# USB_USB2SS_GBL_3100C100h register map
Vendor: Texas Instruments
Registers are 32-bit, read-write, reset 0x0 unless marked. A register's access mark holds for its fields unless they carry their own. Offsets are as the file gives them; [hi:lo] are bit positions; {n}, {i} and the like mark numbered series; <NAME> marks a mode.

## USB2SS_GBL (part 3 of 4)
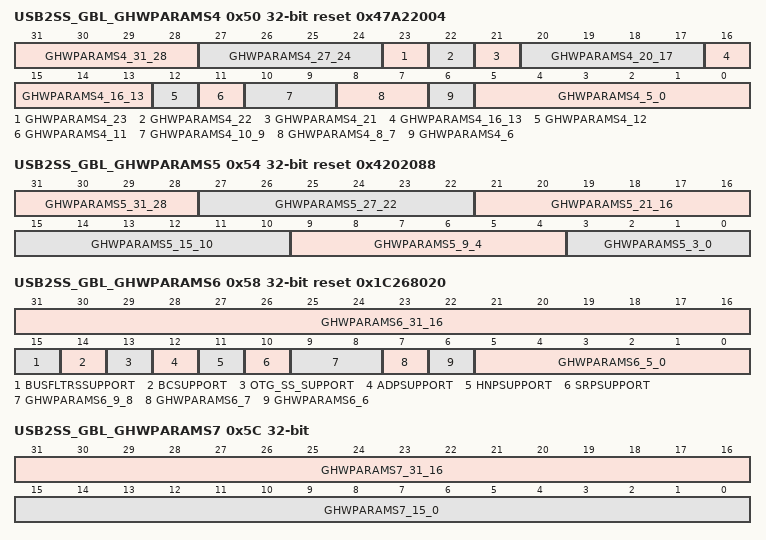
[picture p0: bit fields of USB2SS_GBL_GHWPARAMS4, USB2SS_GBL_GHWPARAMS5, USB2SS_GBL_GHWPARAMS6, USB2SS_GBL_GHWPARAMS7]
0x50 USB2SS_GBL_GHWPARAMS4 ro reset 0x47A22004 — Global Hardware Parameters Register 4This register contains the hardware configuration options that you can select in the coreConsultant GUI. For a description of each parameter, refer to the 'Parameter Descriptions' chapter in the Databook. This information is also available in coreConsultant by right-clicking the parameter label and selecting 'What's This' or by clicking the Help tab. Note: Some of the global hardware parameters are not currently modifiable in coreConsultant. These settings are in the <workspace>/src/DWC_usb3_params.v file. you must not change them.
  [31:28] GHWPARAMS4_31_28 — DWC_USB3_BMU_LSP_DEPTH Reset Source: rst_mod_g_rst_n
  [27:24] GHWPARAMS4_27_24 — DWC_USB3_BMU_PTL_DEPTH-1 Reset Source: rst_mod_g_rst_n
  [23] GHWPARAMS4_23 — DWC_USB3_EN_ISOC_SUPT Reset Source: rst_mod_g_rst_n
  [22] GHWPARAMS4_22 — Reserved Reset Source: rst_mod_g_rst_n
  [21] GHWPARAMS4_21 — DWC_USB3_EXT_BUFF_CONTROL Reset Source: rst_mod_g_rst_n
  [20:17] GHWPARAMS4_20_17 — DWC_USB3_NUM_SS_USB_INSTANCES Reset Source: rst_mod_g_rst_n
  [16:13] GHWPARAMS4_16_13 — DWC_USB3_HIBER_SCRATCHBUFSNumber of external scratchpad buffers the controller requires to save its internal state in the device mode. Each buffer is assumed to be 4KB. The scratchpad buffer array must have this many buffer pointers. Reset Source: rst_mod_g_rst_n
  [12] GHWPARAMS4_12 — Reserved Reset Source: rst_mod_g_rst_n
  [11] GHWPARAMS4_11 — Reserved Reset Source: rst_mod_g_rst_n
  [10:9] GHWPARAMS4_10_9 — Reserved Reset Source: rst_mod_g_rst_n
  [8:7] GHWPARAMS4_8_7 — Reserved Reset Source: rst_mod_g_rst_n
  [6] GHWPARAMS4_6 — Reserved Reset Source: rst_mod_g_rst_n
  [5:0] GHWPARAMS4_5_0 — DWC_USB3_CACHE_TRBS_PER_TRANSFER Reset Source: rst_mod_g_rst_n
0x54 USB2SS_GBL_GHWPARAMS5 ro reset 0x4202088 — Global Hardware Parameters Register 5This register contains the hardware configuration options that you can select in the coreConsultant GUI. For a description of each parameter, refer to the 'Parameter Descriptions' chapter in the Databook. This information is also available in coreConsultant by right-clicking the parameter label and selecting 'What's This' or by clicking the Help tab. Note: Some of the global hardware parameters are not currently modifiable in coreConsultant. These settings are in the <workspace>/src/DWC_usb3_params.v file. you must not change them.
  [31:28] GHWPARAMS5_31_28 — Reserved Reset Source: rst_mod_g_rst_n
  [27:22] GHWPARAMS5_27_22 — DWC_USB3_DFQ_FIFO_DEPTH Reset Source: rst_mod_g_rst_n
  [21:16] GHWPARAMS5_21_16 — DWC_USB3_DWQ_FIFO_DEPTH Reset Source: rst_mod_g_rst_n
  [15:10] GHWPARAMS5_15_10 — DWC_USB3_TXQ_FIFO_DEPTH Reset Source: rst_mod_g_rst_n
  [9:4] GHWPARAMS5_9_4 — DWC_USB3_RXQ_FIFO_DEPTH Reset Source: rst_mod_g_rst_n
  [3:0] GHWPARAMS5_3_0 — DWC_USB3_BMU_BUSGM_DEPTH Reset Source: rst_mod_g_rst_n
0x58 USB2SS_GBL_GHWPARAMS6 ro reset 0x1C268020 — Global Hardware Parameters Register 6This register contains the hardware configuration options that you can select in the coreConsultant GUI. For a description of each parameter, refer to the 'Parameter Descriptions' chapter in the Databook. This information is also available in coreConsultant by right-clicking the parameter label and selecting 'What's This' or by clicking the Help tab. Note: Some of the global hardware parameters are not currently modifiable in coreConsultant. These settings are in the <workspace>/src/DWC_usb3_params.v file. you must not change them.
  [31:16] GHWPARAMS6_31_16 — DWC_USB3_RAM0_DEPTH Reset Source: rst_mod_g_rst_n
  [15] BUSFLTRSSUPPORT — DWC_USB3_EN_BUS_FILTERS Reset Source: rst_mod_g_rst_n
  [14] BCSUPPORT — DWC_USB3_EN_BC Reset Source: rst_mod_g_rst_n
  [13] OTG_SS_SUPPORT — Reserved Reset Source: rst_mod_g_rst_n
  [12] ADPSUPPORT — DWC_USB3_EN_ADP Reset Source: rst_mod_g_rst_n
  [11] HNPSUPPORT — Reserved Reset Source: rst_mod_g_rst_n
  [10] SRPSUPPORT — Reserved Reset Source: rst_mod_g_rst_n
  [9:8] GHWPARAMS6_9_8 — Reserved Reset Source: rst_mod_g_rst_n
  [7] GHWPARAMS6_7 — DWC_USB3_EN_FPGA Reset Source: rst_mod_g_rst_n
  [6] GHWPARAMS6_6 — DWC_USB3_EN_DBG_PORTS Reset Source: rst_mod_g_rst_n
  [5:0] GHWPARAMS6_5_0 — DWC_USB3_PSQ_FIFO_DEPTH Reset Source: rst_mod_g_rst_n
0x5C USB2SS_GBL_GHWPARAMS7 ro — Global Hardware Parameters Register 7This register contains the hardware configuration options that you can select in the coreConsultant GUI. For a description of each parameter, refer to the 'Parameter Descriptions' chapter in the Databook. This information is also available in coreConsultant by right-clicking the parameter label and selecting 'What's This' or by clicking the Help tab. Note: Some of the global hardware parameters are not currently modifiable in coreConsultant. These settings are in the <workspace>/src/DWC_usb3_params.v file. you must not change them.
  [31:16] GHWPARAMS7_31_16 — DWC_USB3_RAM2_DEPTH Reset Source: rst_mod_g_rst_n
  [15:0] GHWPARAMS7_15_0 — DWC_USB3_RAM1_DEPTH Reset Source: rst_mod_g_rst_n
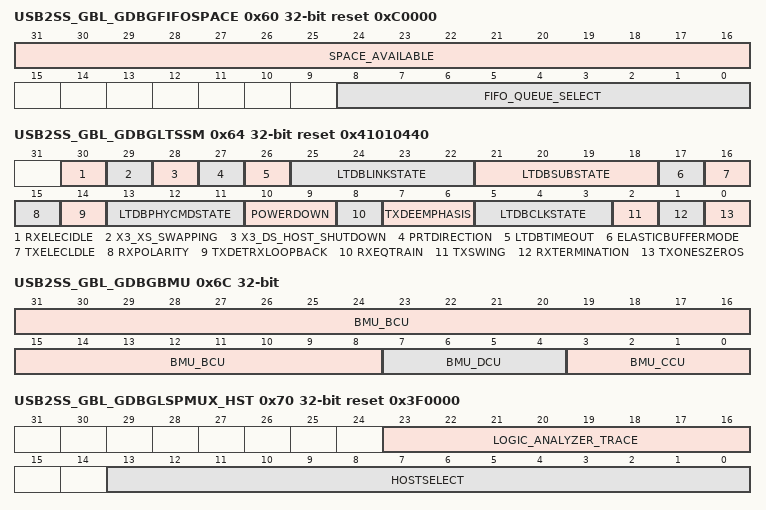
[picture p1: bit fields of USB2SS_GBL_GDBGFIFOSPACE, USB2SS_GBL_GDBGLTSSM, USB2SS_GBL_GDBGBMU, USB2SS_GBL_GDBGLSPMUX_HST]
0x60 USB2SS_GBL_GDBGFIFOSPACE access per field reset 0xC0000 — Global Debug Queue/FIFO Space Available RegisterBit Bash test should not be done on this debug register.
  [31:16] SPACE_AVAILABLE ro — SPACE_AVAILABLE Reset Source: rst_mod_g_rst_n
  [8:0] FIFO_QUEUE_SELECT rw — FIFO/Queue Select [or] Port-Select - FIFO/Queue Select[8:5] indicates the FIFO/Queue Type - FIFO/Queue Select[4:0] indicates the FIFO/Queue NumberFor example, 9'b0_0010_0001 refers to RxFIFO_1 and 9'b0_0101_1110 refers to TxReqQ_30. - 9'b0_0001_1111 to 9'b0_0000_0000: TxFIFO_31 to TxFIFO_0 - 9'b0_0011_1111 to 9'b0_0010_0000: RxFIFO_31 to RxFIFO_0 - 9'b0_0101_1111 to 9'b0_0100_0000: TxReqQ_31 to TxReqQ_0 - 9'b0_0111_1111 to 9'b0_0110_0000: RxReqQ_31 to RxReqQ_0 - 9'b0_1001_1111 to 9'b0_1000_0000: RxInfoQ_31 to RxInfoQ_0 - 9'b0_1010_0000: DescFetchQ_0 [for backwards compatibility] - 9'b0_1010_0001: EventQ_0 [for backwards compatibility] - 9'b0_1010_0010: ProtocolStatusQ_0 - 9'b0_1101_1111 to 9'b0_1110_0000: DescFetchQ_31 to DescFetchQ_0 - 9'b0_1111_1111 to 9'b0_1110_0000: WriteBack/EventQ_31 to WriteBack/EventQ_0 - 9'b1_0000_0111 to 9'b1_0000_0000: AuxEventQ_7 to AuxEventQ_0 [if EN_SEPARATE_DESC_QUEUES=1]Port-Select[3:0] selects the port-number when accessing GDBGLTSSM register. Reset Source: rst_mod_g_rst_n
0x64 USB2SS_GBL_GDBGLTSSM ro reset 0x41010440 — Global Debug LTSSM RegisterIn multi-port host configuration, the port-number is defined by Port-Select[3:0] field in the GDBGFIFOSPACE register. Note: - GDBGLTSSM register is not applicable for USB 2.0-only mode. - Bit Bash test should not be done on this debug register.
  [30] RXELECIDLE — RxElecidleFor description of RxElecIdle, see table 5-4, 'Status Interface Signals' of the PIPE3 Specification. Reset Source: rst_mod_g_rst_n
  [29] X3_XS_SWAPPING — Reserved Reset Source: rst_mod_g_rst_n
  [28] X3_DS_HOST_SHUTDOWN — Reserved Reset Source: rst_mod_g_rst_n
  [27] PRTDIRECTION — Reserved Reset Source: rst_mod_g_rst_n
  [26] LTDBTIMEOUT — LTDB Timeout [LTDBTimeout] Reset Source: rst_mod_g_rst_n
  [25:22] LTDBLINKSTATE — LTDB Link State [LTDBLinkState] Reset Source: rst_mod_g_rst_n
  [21:18] LTDBSUBSTATE — LTDB Sub-State [LTDBSubState] Reset Source: rst_mod_g_rst_n
  [17] ELASTICBUFFERMODE — Elastic Buffer Mode [ElasticBufferMode]For field definition, refer to Table 5-3 of the PIPE3 specification. Reset Source: rst_mod_g_rst_n
  [16] TXELECLDLE — Tx Elec Idle [TxElecIdle]For field definition, refer to Table 5-3 of the PIPE3 specification. Reset Source: rst_mod_g_rst_n
  [15] RXPOLARITY — Rx Polarity [RxPolarity]For field definition, refer to Table 5-3 of the PIPE3 specification. Reset Source: rst_mod_g_rst_n
  [14] TXDETRXLOOPBACK — Tx Detect Rx/Loopback [TxDetRxLoopback]For field definition, refer to Table 5-3 of the PIPE3 specification. Reset Source: rst_mod_g_rst_n
  [13:11] LTDBPHYCMDSTATE — LTSSM PHY command State [LTDBPhyCmdState] - 000: PHY_IDLE [PHY command state is in IDLE. No PHY request pending] - 001: PHY_DET [Request to start Receiver detection] - 010: PHY_DET_3 [Wait for Phy_Status [Receiver detection]] - 011: PHY_PWR_DLY [Delay Pipe3_PowerDown P0 -> P1/P2/P3 request] - 100: PHY_PWR_A [Delay for internal logic] - 101: PHY_PWR_B [Wait for Phy_Status[Power state change request]] Reset Source: rst_mod_g_rst_n
  [10:9] POWERDOWN — POWERDOWN [PowerDown]For field definition, refer to Table 5-3 of the PIPE3 specification. Reset Source: rst_mod_g_rst_n
  [8] RXEQTRAIN — RxEq TrainFor field definition, refer to Table 5-3 of the PIPE3 specification. Reset Source: rst_mod_g_rst_n
  [7:6] TXDEEMPHASIS — TXDEEMPHASIS [TxDeemphasis]For field definition, refer to Table 5-3 of the PIPE3 specification. Reset Source: rst_mod_g_rst_n
  [5:3] LTDBCLKSTATE — LTSSM Clock State [LTDBClkState] In multi-port host configuration, the port number is defined by Port-Select[3:0] field in the GDBGFIFOSPACE register. Note: GDBGLTSSM register is not applicable for USB 2.0-only mode. - 000: CLK_NORM [PHY is in non-P3 state and PCLK is running] - 001: CLK_TO_P3 [P3 entry request to PHY]. - 010: CLK_WAIT1 [Wait for Phy_Status [P3 request]]. - 011: CLK_P3 [PHY is in P3 and PCLK is not running]. - 100: CLK_TO_P0 [P3 exit request to PHY]. - 101: CLK_WAIT2 [Wait for Phy_Status [P3 exit request]] Reset Source: rst_mod_g_rst_n
  [2] TXSWING — Tx Swing [TxSwing]For field definition, refer to Table 5-3 of the PIPE3 specification. Reset Source: rst_mod_g_rst_n
  [1] RXTERMINATION — Rx Termination [RxTermination]For details on DWC_USB3_PIPE_RXTERM_RESET_VAL, refer to <workspace>/src/DWC_usb3_params.v Reset Source: rst_mod_g_rst_n
  [0] TXONESZEROS — Tx Ones/Zeros [TxOnesZeros]For field definition, refer to Table 5-3 of the PIPE3 specification. Reset Source: rst_mod_g_rst_n
0x68 USB2SS_GBL_GDBGLNMCC ro — Global Debug LNMCC RegisterBit Bash test should not be done on this debug register.
  [8:0] LNMCC_BERC — This field indicates the bit error rate information for the port selected in the GDBGFIFOSPACE.PortSelect field. This field is for debug purposes only. Reset Source: rst_mod_g_rst_n
0x6C USB2SS_GBL_GDBGBMU ro — Global Debug BMU RegisterBit Bash test should not be done on this debug register.
  [31:8] BMU_BCU — BMU_BCU Debug information Reset Source: rst_mod_g_rst_n
  [7:4] BMU_DCU — BMU_DCU Debug information Reset Source: rst_mod_g_rst_n
  [3:0] BMU_CCU — BMU_CCU Debug information Reset Source: rst_mod_g_rst_n
0x70 USB2SS_GBL_GDBGLSPMUX_HST reset 0x3F0000 — Global Debug LSP MUX Register - HostThis register is for internal use only.If DWC_USB3_PRESERVE_LOGIC_ANALYZER_SELECT is enabled during controller configuration, then the default values readout is X (Undefined).Bit Bash test should not be done on this debug register.
  [23:16] LOGIC_ANALYZER_TRACE — logic_analyzer_trace Port MUX SelectCurrently only bits[21:16] are used. For details on how the mux controls the debug traces, refer to the 'assign logic_analyzer_trace =' code section in the DWC_usb3.v file.A value of 6'h3F drives 0s on the logic_analyzer_trace signal. If you plan to OR [instead using a mux] this signal with other trace signals in your system to generate a common trace signal, you can use this feature. Reset Source: rst_mod_g_rst_n
  [13:0] HOSTSELECT — Device LSP SelectSelects the LSP debug information presented in the GDBGLSP register in host mode. Reset Source: rst_mod_g_rst_n
0x74 USB2SS_GBL_GDBGLSP ro — Global Debug LSP RegisterThis register is for internal debug purposes only.This register is for internal use only.If DWC_USB3_PRESERVE_LOGIC_ANALYZER_SELECT is enabled during controller configuration, then the default values readout is X (Undefined).Bit Bash test should not be done on this debug register.
  [31:0] LSPDEBUG — LSP Debug Information Reset Source: rst_mod_g_rst_n
0x78 USB2SS_GBL_GDBGEPINFO0 ro — Global Debug Endpoint Information Register 0This register is for internal use only.If DWC_USB3_PRESERVE_LOGIC_ANALYZER_SELECT is enabled during controller configuration, then the default values readout is X (Undefined).Bit Bash test should not be done on this debug register.
  [31:0] EPDEBUG — Endpoint Debug Information, bits[31:0] Reset Source: rst_mod_g_rst_n
0x7C USB2SS_GBL_GDBGEPINFO1 ro reset 0x800000 — Global Debug Endpoint Information Register 1This register is for internal use only.If DWC_USB3_PRESERVE_LOGIC_ANALYZER_SELECT is enabled during controller configuration, then the default values readout is X (Undefined).Bit Bash test should not be done on this debug register.
  [31:0] EPDEBUG — Endpoint Debug Information, bits[63:32] Reset Source: rst_mod_g_rst_n
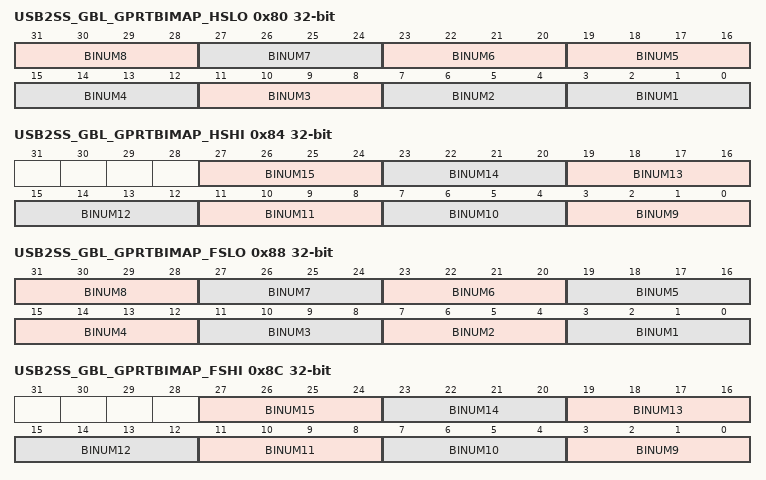
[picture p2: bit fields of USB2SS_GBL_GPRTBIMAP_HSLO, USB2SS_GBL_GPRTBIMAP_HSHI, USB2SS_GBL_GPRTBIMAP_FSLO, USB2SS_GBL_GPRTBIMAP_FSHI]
0x80 USB2SS_GBL_GPRTBIMAP_HSLO access per field — Global High-Speed Port to Bus Instance Mapping Register - LowThis is an alternate register for the GPRTBIMAP_HS register. - Register fields are read-write with respect to number of port instantiated. writeAsRead constraint is added to limit side effects for unused fields. Note: For reset values, refer to the corresponding values in the GPRTBIMAP_HS register.
  [31:28] BINUM8 ro — BINUM8: HS USB Instance Number for Port 8. Application-programmable ID field. Reset Source: rst_mod_g_rst_n
  [27:24] BINUM7 ro — BINUM7: HS USB Instance Number for Port 7. Application-programmable ID field. Reset Source: rst_mod_g_rst_n
  [23:20] BINUM6 ro — BINUM6 USB Instance Number for Port 6. Application-programmable ID field. Reset Source: rst_mod_g_rst_n
  [4n-1:4n-4] BINUM{n} ro (n=2..5) — BINUM{n}: HS USB Instance Number for Port {n}.Application-programmable ID field. Reset Source: rst_mod_g_rst_n
  [3:0] BINUM1 rw — BINUM1: HS USB Instance Number for Port 1. Application-programmable ID field. Reset Source: rst_mod_g_rst_n
0x84 USB2SS_GBL_GPRTBIMAP_HSHI ro — Global High-Speed Port to Bus Instance Mapping Register - HighThis is an alternate register for the GPRTBIMAP_HS register. - Register fields are read-write with respect to number of port instantiated. writeAsRead constraint is added to limit side effects for unused fields. Note: For reset values, refer to the corresponding values in the GPRTBIMAP register.
  [27:24] BINUM15 — BINUM15: HS USB Instance Number for Port 15.Application-programmable ID field. Reset Source: rst_mod_g_rst_n
  [23:20] BINUM14 — BINUM14: HS USB Instance Number for Port 14.Application-programmable ID field. Reset Source: rst_mod_g_rst_n
  [19:16] BINUM13 — BINUM13: HS USB Instance Number for Port 13.Application-programmable ID field. Reset Source: rst_mod_g_rst_n
  [15:12] BINUM12 — BINUM12: HS USB Instance Number for Port 12.SApplication-programmable ID field. Reset Source: rst_mod_g_rst_n
  [11:8] BINUM11 — BINUM11: HS USB Instance Number for 11.Application-programmable ID field. Reset Source: rst_mod_g_rst_n
  [7:4] BINUM10 — BINUM10: HS USB Instance Number for Port 10.Application-programmable ID field. Reset Source: rst_mod_g_rst_n
  [3:0] BINUM9 — BINUM9: HS USB Instance Number for Port 9.Application-programmable ID field. Reset Source: rst_mod_g_rst_n
0x88 USB2SS_GBL_GPRTBIMAP_FSLO access per field — Global Full-Speed Port to Bus Instance Mapping Register - LowThis is an alternate register for the GPRTBIMAP_FS register. - Register fields are read-write with respect to number of port instantiated. writeAsRead constraint is added to limit side effects for unused fields. Note: For reset values, refer to the corresponding values in the GPRTBIMAP_FS register.
  [31:28] BINUM8 ro — BINUM8: FS USB Instance Number for Port 8.Application-programmable ID field. Reset Source: rst_mod_g_rst_n
  [27:24] BINUM7 ro — BINUM7: FS USB Instance Number for Port 7. Application-programmable ID field. Reset Source: rst_mod_g_rst_n
  [4n-1:4n-4] BINUM{n} ro (n=2..6) — BINUM{n}: FS USB Instance Number for Port {n}.Application-programmable ID field. Reset Source: rst_mod_g_rst_n
  [3:0] BINUM1 rw — BINUM1: FS USB Instance Number for Port 1.Application-programmable ID field. Reset Source: rst_mod_g_rst_n
0x8C USB2SS_GBL_GPRTBIMAP_FSHI ro — Global Full-Speed Port to Bus Instance Mapping Register - HighThis is an alternate register for the GPRTBIMAP_FS register. - Register fields are read-write with respect to number of port instantiated. writeAsRead constraint is added to limit side effects for unused fields. Note: For reset values, refer to the corresponding values in the GPRTBIMAP_FS register.
  [4n-33:4n-36] BINUM{n} (n=11..15) — BINUM{n}: FS USB Instance Number for Port {n}.Application-programmable ID field Reset Source: rst_mod_g_rst_n
  [7:4] BINUM10 — BINUM10: FS USB Instance Number for Port 10. Application-programmable ID field Reset Source: rst_mod_g_rst_n
  [3:0] BINUM9 — BINUM9: FS USB Instance Number for Port 9.Application-programmable ID field. Reset Source: rst_mod_g_rst_n
0x94 USB2SS_GBL_Reserved_94 ro — Future Reserved Register at offset 0x94
  [31:0] RESERVED_31_0 — Future use Register field
0x98 USB2SS_GBL_Reserved_98 ro — Future Reserved Register at offset 0x98
  [31:0] RESERVED_31_0 — Field for future use
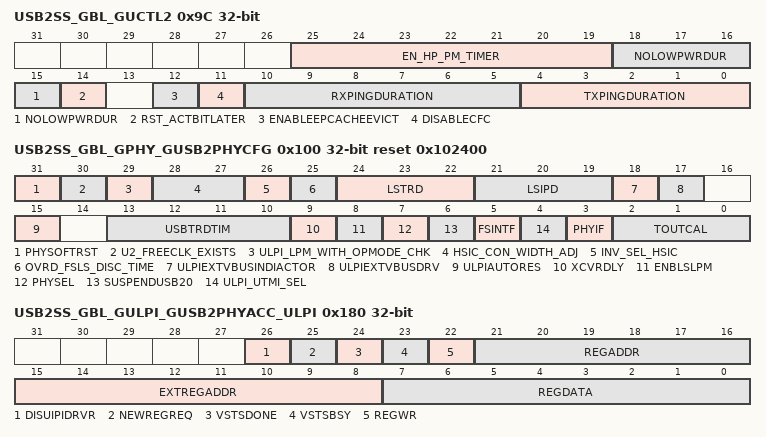
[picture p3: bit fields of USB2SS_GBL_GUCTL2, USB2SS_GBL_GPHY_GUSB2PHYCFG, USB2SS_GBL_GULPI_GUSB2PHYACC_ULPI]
0x9C USB2SS_GBL_GUCTL2 access per field — Global User Control Register 2: This register provides a few options for the software to control the controller behavior in the Host and device mode. Most of the options are used to improve inter-operability with different hosts and devices.
  [25:19] EN_HP_PM_TIMER rw — This register field is used to set new HP and PM timers. - To enable PM timer, set GUCTL2[19] bit as 1. - To enable HP timer, set GUCTL2[20] bit as 1. Default value of HP timer is 4us when HP PM timer is not enabled. when new HP timer is enabled default value is 12us.Use GUCTL2[25:21] to specify HP timer value in microseconds. Reset Source: rst_mod_g_rst_n
  [18:15] NOLOWPWRDUR rw — No Low Power Duration [NOLOWPWRDUR]This bit is applicable for device mode only and is ignored in host mode.After starting a transfer on a SS ISOC endpoint, the application must program these bits to prevent the device to lose frame synchronization over a period of time.Based on this count-down counter, the device will wake itself from U1/U2 low power states. After entering to U0 state and receiving two ITPs [which will sync-up the host and the device], U1/U2 low power entry is allowed.Each count represents the duration in terms of milliseconds. For example, a value of 3 represents 3ms.Note: - To disable this feature, set this field to 4'b0. - These bits are applicable only in device mode and ignored in host mode. - Some xHCI hosts do not send ITPs when performing ISOC transfers when the link enters U1/U2 low power states. This causes the device to lose frame synchronization over a period of time resulting in ISOC packets being dropped. Reset Source: rst_mod_g_rst_n
  [14] RST_ACTBITLATER rw — Enable clearing of the command active bit for the ENDXFER command after the command execution is completed. This bit is valid in device mode only. Reset Source: rst_mod_g_rst_n
  [12] ENABLEEPCACHEEVICT rw — Enable Evicting Endpoint cache after Flow Control for bulk endpoints.In 3.00a release, a performance enhancement was done to keep the non-stream capable bulk IN endpoint in cache after flow control. Setting this bit will disable this enhancement. This should be set only for debug purpose. Reset Source: rst_mod_g_rst_n
  [11] DISABLECFC rw — Disable xHCI Errata Feature Contiguous Frame ID CapabilityThis field controls the xHCI Errata feature Contiguous FrameID capability. When set, the xHCI HCCPARAMS1 bit 11 will be set to 0 indicating that CFC is not supported. Disable this feature only if your application cannot tolerate Misssed Service Error events for Isoc transfers, and your system latencies are large to cause Missed Service errors even if the software is following the Isochronous Thresholding rules. Reset Source: rst_mod_g_rst_n
  [10:5] RXPINGDURATION rw — Recieve Ping Maximum Duration This field is relevant to Host mode and controls the maximum duration of received LFPS to be treated as a Ping LFPS. The Max duration of the Ping LFPS is controlled by programming this value and is in terms of 8 ns granularity. Eg: A value of 32 indicates 256 ns. Reset Source: rst_mod_g_rst_n
  [4:0] TXPINGDURATION rw — Transmit Ping Maximum Duration This field is relevant to Device mode and controls the maximum duration for which the controller should instruct the PHY to transmit a Ping LFPS. The duration of the Ping LFPS is controlled by programming this value and is in terms of 8 ns granularity. Eg: A value of 13 indicates 104 ns. Reset Source: rst_mod_g_rst_n
0x100 USB2SS_GBL_GPHY access not given reset not defined
0x100 USB2SS_GBL_GPHY_GUSB2PHYCFG access per field reset 0x102400 — Global USB2 PHY Configuration RegisterThe application must program this register before starting any transactions on either the SoC bus or the USB.In Device-only configurations, only one register is needed.In Host mode, per-port registers are implemented.
  [31] PHYSOFTRST rw — UTMI PHY Soft Reset [PHYSoftRst]Causes the usb2phy_reset signal to be asserted to reset a UTMI PHY. Not applicable to ULPI because ULPI PHYs are reset via their FunctionControl.Reset register, and the controller automatically writes to this register when the controller is reset [vcc_reset_n, USBCMD.HCRST, DCTL.SoftReset, or GCTL.SoftReset] Reset Source: rst_mod_g_rst_n
  [30] U2_FREECLK_EXISTS rw — U2_FREECLK_EXISTSSpecifies whether your USB 2.0 PHY provides a free-running PHY clock, which is active when the clock control input is active.If your USB 2.0 PHY provides a free-running PHY clock, it must be connected to the utmi_clk[0] input. The remaining utmi_clk[n] must be connected to the respective port clocks. The controller uses the Port-0 clock for generating the internal mac2 clock. - 1'b0: USB 2.0 free clock does not exist - 1'b1: USB 2.0 free clock existsNote: When the controller is configured as device-only [DWC_USB3_MODE = 0], do not set this bit to 1. Reset Source: rst_mod_g_rst_n
  [29] ULPI_LPM_WITH_OPMODE_CHK rw — ULPI_LPM_WITH_OPMODE_CHKSupport the LPM over ULPI without NOPID token to the ULPI PHY. If this bit is set, the ULPI PHY is expected to qualify the EXT PID with OPMODE=2'b00 for LPM and not treat it as a NOPID. Check with your PHY vendor about your PHY behavior. This bit is valid only when the DWC_USB3_HSPHY_INTERFACE parameter is 2 or 3. - 1'b0: A NOPID is sent before sending an EXTPID for LPM. - 1'b1: An EXTPID is sent without previously sending a NOPID. Note: This bit is valid only in host mode. This bit should be '0' for Synopsys PHY. Reset Source: rst_mod_g_rst_n
  [28:27] HSIC_CON_WIDTH_ADJ ro — HSIC_CON_WIDTH_ADJThis bit is used in the HSIC device mode of operation. By default, the connect duration for the HSIC device controller is thrice the strobe period. You can change this duration to 4, 5, or 6 times the strobe period by setting the value of this field to 1, 2, or 3. This value is added to the default connect duration. Reset Source: rst_mod_g_rst_n
  [26] INV_SEL_HSIC ro — INV_SEL_HSICThe application driver uses this bit to control the HSIC enable/disable function. When set to '1', this bit overrides and functionally inverts the 'if_select_hsic' input signal.If {INV_SEL_HSIC, if_select_hsic} is: - 00: HSIC Capability is disabled. - 01: HSIC Capability is enabled. - 10: HSIC Capability is enabled. - 11: HSIC Capability is disabled.If the controller operates as non-HSIC-capable, it can only connect to non-HSIC-capable PHYs. If it operates as HSIC-capable, it can connect to HSIC-capable PHYs.This bit is reserved if the DWC_USB3_ENABLE_HSIC parameter is set to '0'. When selecting the HSIC feature, set the host side to HSIC mode first, then set the device mode side. If the device side is set to HSIC mode first and if the host does not see a connection in HSIC mode, then you must de-select the device HSIC mode and select it again using the if_select_hsic setting or register bit GUSB2PHYCFGn[26] to ensure that the device can connect to the host. Reset Source: rst_mod_g_rst_n
  [25] OVRD_FSLS_DISC_TIME rw — Overriding the FS/LS disconnect time to 32us. - If this value is 0, the FS/LS disconnect time is set to 2.5us as per the USB specification. - If this value is non-0, the disconnect detection time is set to 32us.Normally, this value is set to 0. However, if the USB 2.0 PHYs introduce noise on the UTMI linestate and cause SE0 glitches longer than 2.5us, then a false disconnect condition may get triggered. To avoid interoperability issues with these PHYs, this bit can be set to 1. Reset Source: rst_mod_g_rst_n
  [24:22] LSTRD rw — LS Turnaround Time [LSTRDTIM]This field indicates the value of the Rx-to-Tx packet gap for LS devices. The encoding is as follows: - 0: 2 bit times - 1: 2.5 bit times - 2: 3 bit times - 3: 3.5 bit times - 4: 4 bit times - 5: 4.5 bit times - 6: 5 bit times - 7: 5.5 bit timesNote: - This field is applicable only in Host mode. - For normal operation [to work with most LS devices], set the default value of this field to 3'h0 [2 bit times]. - The programmable LS device inter-packet gap and turnaround delays are provided to support some legacy LS devices that might require different delays than the default/fixed ones. For instance, the Open LS mouse requires 3 bit times of inter-packet gap to work correctly. - Include your PHY delays when programming the LSIPD/LSTRDTIM values. For example, if your PHY's TxEndDelay in LS mode is 30 UTMI/ULPI CLKs, then subtract this delay [~1 LS bit time] from the device's delay requirement. Reset Source: rst_mod_g_rst_n
  [21:19] LSIPD rw — LS Inter-Packet Time [LSIPD]This field indicates the value of Tx-to-Tx packet gap for LS devices. The encoding is as follows: - 0: 2 bit times - 1: 2.5 bit times - 2: 3 bit times - 3: 3.5 bit times - 4: 4 bit times - 5: 4.5 bit times - 6: 5 bit times - 7: 5.5 bit timesNote: - This field is applicable only in Host mode. - For normal operation [to work with most LS devices], set the default value of this field to 3'h2 [3 bit times]. - The programmable LS device inter-packet gap and turnaround delays are provided to support some legacy LS devices that might require different delays than the default/fixed ones. For instance, the AOpen LS mouse requires 3 bit times of inter-packet gap to work correctly. - Include your PHY delays when programming the LSIPD/LSTRDTIM values. For example, if your PHY's TxEndDelay in LS mode is 30 UTMI/ULPI CLKs, then subtract this delay [~1 LS bit time] from the device's delay requirement. Reset Source: rst_mod_g_rst_n
  [18] ULPIEXTVBUSINDIACTOR rw — ULPI External VBUS Indicator [ULPIExtVbusIndicator]Indicates the ULPI PHY VBUS over-current indicator. - 1'b0: PHY uses an internal VBUS valid comparator. - 1'b1: PHY uses an external VBUS valid comparator.Valid only when RTL parameter DWC_USB3_HSPHY_INTERFACE = 2 or 3 Reset Source: rst_mod_g_rst_n
  [17] ULPIEXTVBUSDRV rw — ULPI External VBUS Drive [ULPIExtVbusDrv]Selects supply source to drive 5V on VBUS, in the ULPI PHY. - 1'b0: PHY drives VBUS with internal charge pump [default]. - 1'b1: PHY drives VBUS with an external supply.[Only when RTL parameter DWC_USB3_HSPHY_INTERFACE = 2 or 3] Reset Source: rst_mod_g_rst_n
  [15] ULPIAUTORES rw — ULPI Auto Resume [ULPIAutoRes]Sets the AutoResume bit in Interface Control register on the ULPI PHY. - 1'b0: PHY does not use the AutoResume feature. - 1'b1: PHY uses the AutoResume feature.Valid only when RTL parameter DWC_USB3_HSPHY_INTERFACE = 2 or 3 Reset Source: rst_mod_g_rst_n
  [13:10] USBTRDTIM rw — USB 2.0 Turnaround Time [USBTrdTim]Sets the turnaround time in PHY clocks.Specifies the response time for a MAC request to the Packet FIFO Controller [PFC] to fetch data from the DFIFO [SPRAM].The following are the required values for the minimum SoC bus frequency of 60 MHz. USB turnaround time is a critical certification criteria when using long cables and five hub levels.The required values for this field: - 4'h5: When the MAC interface is 16-bit UTMI+. - 4'h9: When the MAC interface is 8-bit UTMI+/ULPI.If SoC bus clock is less than 60 MHz, and USB turnaround time is not critical, this field can be set to a larger value.Note: This field is valid only in device mode. Reset Source: rst_mod_g_rst_n
  [9] XCVRDLY rw — Transceiver Delay: Enables a delay between the assertion of the UTMI/ULPI Transceiver Select signal [for HS] and the assertion of the TxValid signal during a HS Chirp.When this bit is set to 1, a delay [of approximately 2.5 us] is introduced from the time when the Transceiver Select is set to 2'b00 [HS] to the time the TxValid is driven to 0 for sending the chirp-K. This delay is required for some UTMI/ULPI PHYs.Note: - If you enable the hibernation feature when the device controller comes out of power-off, you must re-initialize this bit with the appropriate value because the controller does not save and restore this bit value during hibernation. - This bit is valid only in device mode. Reset Source: rst_mod_g_rst_n
  [8] ENBLSLPM rw — Enable utmi_sleep_n and utmi_l1_suspend_n [EnblSlpM]The application uses this bit to control utmi_sleep_n and utmi_l1_suspend_n assertion to the PHY in the L1 state. - 1'b0: utmi_sleep_n and utmi_l1_suspend_n assertion from the controller is not transferred to the external PHY. - 1'b1: utmi_sleep_n and utmi_l1_suspend_n assertion from the controller is transferred to the external PHY.Note: This bit must be set high for Port0 if Synopsys PHY is used.Note: In Device mode - Before issuing any device endpoint command when operating in 2.0 speeds, disable this bit and enable it after the command completes. Without disabling this bit, if a command is issued when the device is in L1 state and if mac2_clk [utmi_clk/ulpi_clk] is gated off, the command will not get completed. Reset Source: rst_mod_g_rst_n
  [7] PHYSEL wo — USB 2.0 High-Speed PHY or USB 1.1 Full-Speed Serial Transceiver Select The application uses this bit to select a high-speed PHY or a full-speed transceiver. - 1'b0: USB 2.0 high-speed UTMI+ or ULPI PHY. This bit is always 0, with Write Only access. - 1'b1: USB 1.1 full-speed serial transceiver. This bit is always 1, with Write Only access.If both interface types are selected in coreConsultant [that is, parameters' values are not zero], the application uses this bit to select the active interface is active, with Read-Write bit access.Note: USB 1.1 full-serial transceiver is not supported. This bit always reads as 1'b0. Reset Source: rst_mod_g_rst_n
  [6] SUSPENDUSB20 rw — Suspend USB2.0 HS/FS/LS PHY [SusPHY]When set, USB2.0 PHY enters Suspend mode if Suspend conditions are valid.For DRD configurations, it is recommended that this bit is set to 0 during coreConsultant configuration. If it is set to 1, then the application must clear this bit after power-on reset. Application needs to set it to 1 after the controller initialization completes.For all other configurations, this bit can be set to 1 during controller configuration.Note: - In host mode, on reset, this bit is set to 1. Software can override this bit after reset. - In device mode, before issuing any device endpoint command when operating in 2.0 speeds, disable this bit and enable it after the command completes. If you issue a command without disabling this bit when the device is in L2 state and if mac2_clk [utmi_clk/ulpi_clk] is gated off, the command will not get completed. Reset Source: rst_mod_g_rst_n
  [5] FSINTF ro — Full-Speed Serial Interface Select [FSIntf]The application uses this bit to select a unidirectional or bidirectional USB 1.1 full-speed serial transceiver interface. - 1'b0: 6-pin unidirectional full-speed serial interface. This bit is set to 0 with Read Only access. - 1'b1: 3-pin bidirectional full-speed serial interface. This bit is set to 0 with Read Only access.Note: USB 1.1 full-speed serial interface is not supported. This bit always reads as 1'b0. Reset Source: rst_mod_g_rst_n
  [4] ULPI_UTMI_SEL ro — ULPI or UTMI+ Select [ULPI_UTMI_Sel]The application uses this bit to select a UTMI+ or ULPI Interface. - 1'b0: UTMI+ Interface - 1'b1: ULPI InterfaceThis bit is writable only if UTMI+ and ULPI is specified for High-Speed PHY Interface[s] in coreConsultant configuration [DWC_USB3_HSPHY_INTERFACE = 3]. Otherwise, this bit is read-only and the value depends on the interface selected through DWC_USB3_HSPHY_INTERFACE. Reset Source: rst_mod_g_rst_n
  [3] PHYIF rw — PHY Interface [PHYIf]If UTMI+ is selected, the application uses this bit to configure the controller to support a UTMI+ PHY with an 8- or 16-bit interface. - 1'b0: 8 bits - 1'b1: 16 bitsULPI Mode: 1'b0Note: - All the enabled 2.0 ports must have the same clock frequency as Port0 clock frequency [utmi_clk[0]]. - The UTMI 8-bit and 16-bit modes cannot be used together for different ports at the same time [that is, all the ports must be in 8-bit mode, or all of them must be in 16-bit mode, at a time]. - If any of the USB 2.0 ports is selected as ULPI port for operation, then all the USB 2.0 ports must be operating at 60 MHz. Reset Source: rst_mod_g_rst_n
  [2:0] TOUTCAL rw — HS/FS Timeout Calibration [TOutCal]The number of PHY clocks, as indicated by the application in this field, is multiplied by a bit-time factor. this factor is added to the high-speed/full-speed interpacket timeout duration in the controller to account for additional delays introduced by the PHY. This may be required, since the delay introduced by the PHY in generating the linestate condition may vary among PHYs.The USB standard timeout value for high-speed operation is 736 to 816 [inclusive] bit times. The USB standard timeout value for full-speed operation is 16 to 18 [inclusive] bit times. The application must program this field based on the speed of connection. The number of bit times added per PHY clock are:High-speed operation: - One 30-MHz PHY clock = 16 bit times - One 60-MHz PHY clock = 8 bit timesFull-speed operation: - One 30-MHz PHY clock = 0.4 bit times - One 60-MHz PHY clock = 0.2 bit times - One 48-MHz PHY clock = 0.25 bit times Reset Source: rst_mod_g_rst_n
0x140 USB2SS_GBL_GI2C access not given reset not defined
0x140 USB2SS_GBL_GI2C_GUSB2I2CCTL ro — Reserved Register
0x180 USB2SS_GBL_GULPI access not given reset not defined
0x180 USB2SS_GBL_GULPI_GUSB2PHYACC_ULPI ro — Global USB 2.0 ULPI PHY Vendor Control RegisterThe application uses this register to access the PHY registers. This register is always implemented when the ULPI PHY Interface is enabled during coreConsultant configuration (parameter DWC_USB3_HSPHY_INTERFACE = 2 or 3).For an ULPI PHY, the controller uses the ULPI interface for PHY register access.The application sets the Vendor Control register for PHY register access and times the PHY register access. The application polls the VStatus Done bit in this register for the completion of the PHY register access.In Device-only configurations, only one register is needed. In Host mode, per-port registers are implemented.
  [26] DISUIPIDRVR — DISUIPIDRVR Reset Source: rst_mod_g_rst_n
  [25] NEWREGREQ — New Register Request The application sets this bit for a new vendor control access.Setting this bit to 1 asserts the utmi_vcontrolload_n [1'b0] on the UTMI interface. Reset Source: rst_mod_g_rst_n
  [24] VSTSDONE — VSTSDONE Reset Source: rst_mod_g_rst_n
  [23] VSTSBSY — VSTSBSY Reset Source: rst_mod_g_rst_n
  [22] REGWR — Register Write The application sets this bit for register writes and clears it for register reads.Note: This bit is applicable for ULPI register read/write access only. Reset Source: rst_mod_g_rst_n
  [21:16] REGADDR — Register Address The 6-bit PHY register address for immediate PHY Register Set access.Set to 6'h2F for Extended PHY Register Set access.Note: These bits are applicable for ULPI only. Reset Source: rst_mod_g_rst_n
  [15:8] EXTREGADDR — EXTREGADDR Reset Source: rst_mod_g_rst_n
  [7:0] REGDATA — REGDATA Reset Source: rst_mod_g_rst_n
